AUTOSAR XML (schema 00048)
package /HuaweiMDC/FunctionalSoftware/SammAnalysis/Execution
  executable SammAnalysisExecutable
    root sw component prototype SammAnalysisRootSwComponent: application-type=SammAnalysisApplicationSwComponent
package /HuaweiMDC/FunctionalSoftware/SammAnalysis/SwComponent
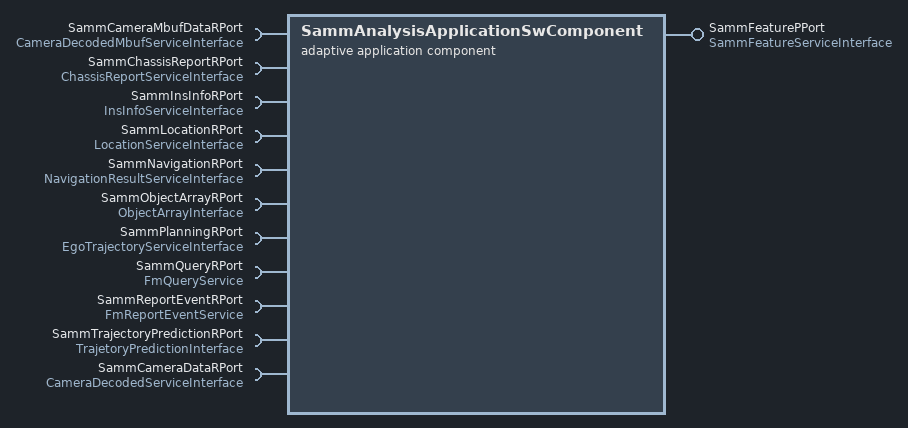
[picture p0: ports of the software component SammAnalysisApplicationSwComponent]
  adaptive application sw component type SammAnalysisApplicationSwComponent
    require port SammCameraMbufDataRPort: required-interface=CameraDecodedMbufServiceInterface
    require port SammChassisReportRPort: required-interface=ChassisReportServiceInterface
    provide port SammFeaturePPort: provided-interface=SammFeatureServiceInterface
    9 x require port:
      SammInsInfoRPort: required-interface=InsInfoServiceInterface
      SammLocationRPort: required-interface=LocationServiceInterface
      SammNavigationRPort: required-interface=NavigationResultServiceInterface
      SammObjectArrayRPort: required-interface=ObjectArrayInterface
      SammPlanningRPort: required-interface=EgoTrajectoryServiceInterface
      SammQueryRPort: required-interface=FmQueryService
      SammReportEventRPort: required-interface=FmReportEventService
      SammTrajectoryPredictionRPort: required-interface=TrajetoryPredictionInterface
      SammCameraDataRPort: required-interface=CameraDecodedServiceInterface
